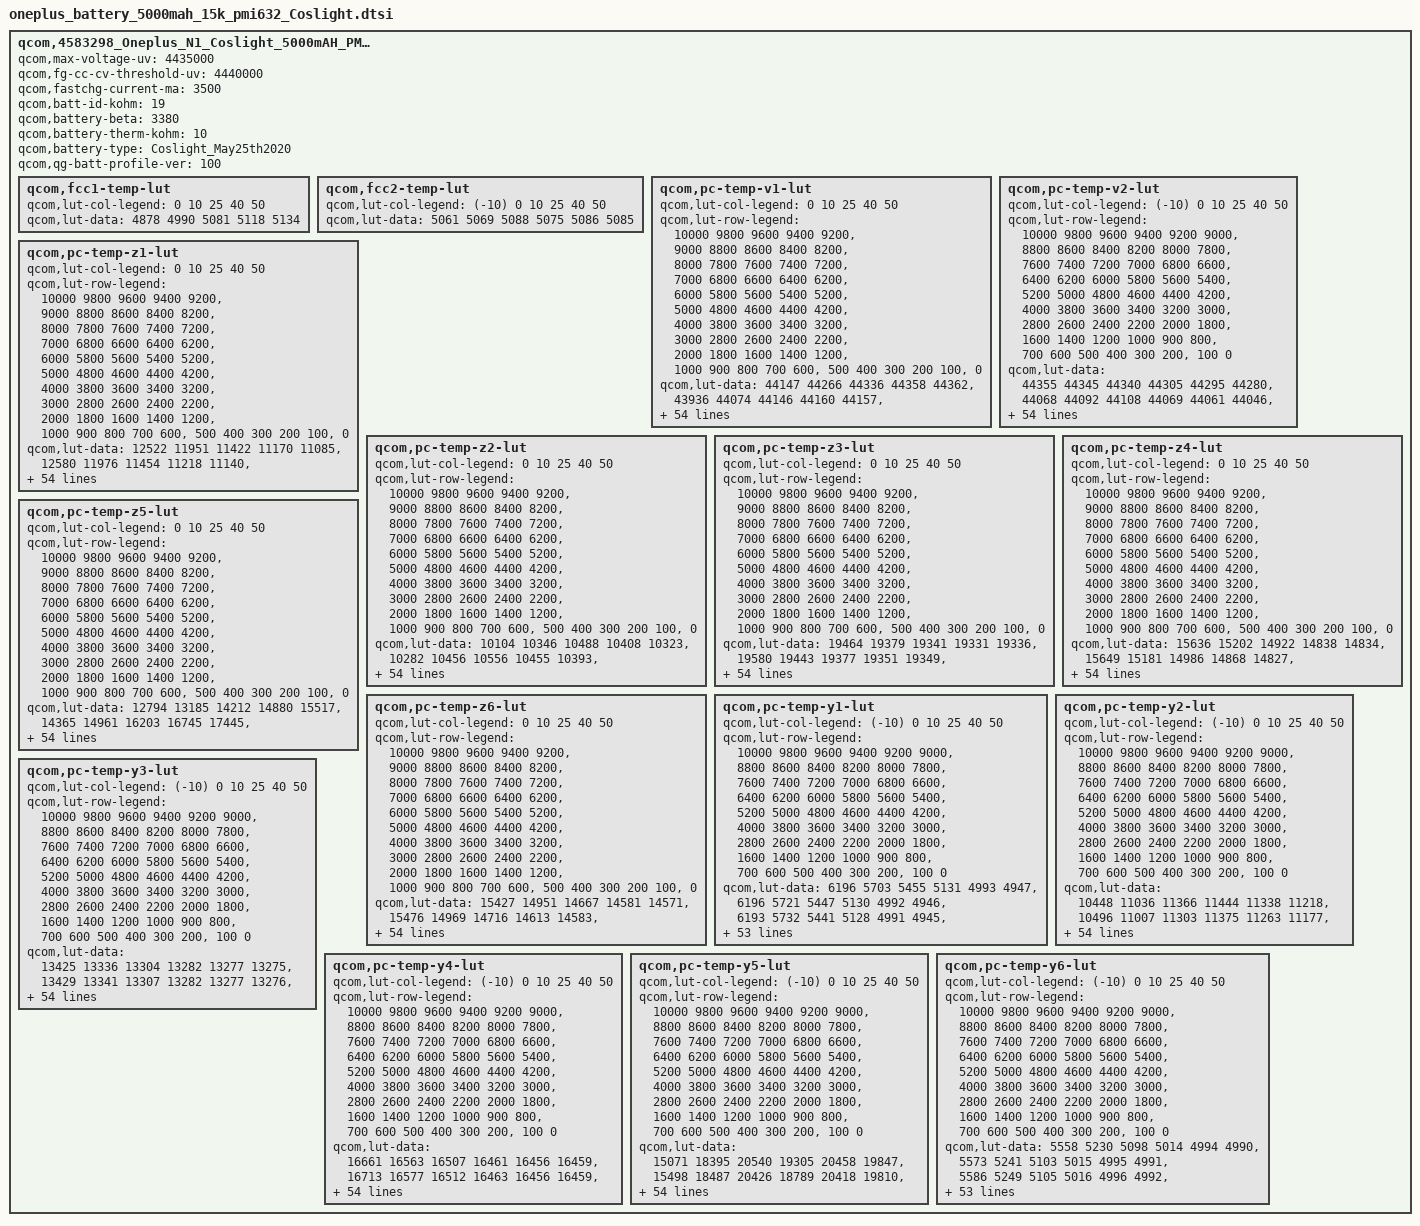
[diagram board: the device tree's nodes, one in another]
qcom,4583298_Oneplus_N1_Coslight_5000mAH_PMI632 {
    /* 4583298_Oneplus_N1_Coslight_5000mAH_PMI632_averaged_MasterSlave_May25th2020 */
    qcom,max-voltage-uv = <4435000>;
    qcom,fg-cc-cv-threshold-uv = <4440000>;
    qcom,fastchg-current-ma = <3500>;
    qcom,batt-id-kohm = <19>;
    qcom,battery-beta = <3380>;
    qcom,battery-therm-kohm = <10>;
    qcom,battery-type = "Coslight_May25th2020";
    qcom,qg-batt-profile-ver = <100>;

	qcom,fcc1-temp-lut {
		qcom,lut-col-legend = <0 10 25 40 50>;
		qcom,lut-data = <4878 4990 5081 5118 5134>;
	};

	qcom,fcc2-temp-lut {
		qcom,lut-col-legend = <(-10) 0 10 25 40 50>;
		qcom,lut-data = <5061 5069 5088 5075 5086 5085>;
	};

	qcom,pc-temp-v1-lut {
		qcom,lut-col-legend = <0 10 25 40 50>;
		qcom,lut-row-legend = <10000 9800 9600 9400 9200>,
			<9000 8800 8600 8400 8200>,
			<8000 7800 7600 7400 7200>,
			<7000 6800 6600 6400 6200>,
			<6000 5800 5600 5400 5200>,
			<5000 4800 4600 4400 4200>,
			<4000 3800 3600 3400 3200>,
			<3000 2800 2600 2400 2200>,
			<2000 1800 1600 1400 1200>,
			<1000 900 800 700 600>,
			<500 400 300 200 100>,
			<0>;
		qcom,lut-data = <44147 44266 44336 44358 44362>,
			<43936 44074 44146 44160 44157>,
			<43718 43872 43955 43970 43971>,
			<43496 43660 43757 43776 43778>,
			<43267 43437 43546 43571 43574>,
			<43026 43206 43322 43352 43359>,
			<42779 42966 43089 43123 43132>,
			<42536 42720 42845 42885 42895>,
			<42294 42474 42595 42638 42646>,
			<42056 42227 42347 42391 42400>,
			<41822 41985 42099 42144 42155>,
			<41592 41747 41856 41899 41912>,
			<41371 41517 41615 41657 41672>,
			<41162 41295 41381 41419 41435>,
			<40952 41082 41159 41189 41204>,
			<40730 40869 40945 40965 40977>,
			<40502 40648 40730 40749 40757>,
			<40292 40429 40514 40542 40547>,
			<40101 40229 40308 40342 40345>,
			<39922 40047 40127 40155 40156>,
			<39756 39862 39951 39977 39980>,
			<39602 39664 39721 39767 39777>,
			<39436 39460 39412 39481 39503>,
			<39238 39239 39160 39219 39239>,
			<39036 38989 39011 39055 39068>,
			<38864 38803 38893 38929 38938>,
			<38706 38705 38781 38806 38812>,
			<38588 38632 38677 38685 38689>,
			<38514 38555 38579 38575 38576>,
			<38457 38480 38484 38475 38474>,
			<38404 38411 38396 38384 38382>,
			<38356 38344 38318 38303 38297>,
			<38312 38284 38249 38229 38220>,
			<38273 38229 38185 38161 38147>,
			<38238 38180 38129 38097 38079>,
			<38203 38135 38077 38037 38012>,
			<38172 38097 38028 37977 37943>,
			<38135 38059 37983 37918 37871>,
			<38075 38000 37922 37847 37789>,
			<37987 37907 37830 37753 37689>,
			<37883 37799 37720 37643 37576>,
			<37756 37680 37604 37523 37454>,
			<37610 37541 37471 37387 37317>,
			<37440 37371 37306 37224 37152>,
			<37289 37223 37158 37083 37014>,
			<37196 37130 37071 37003 36944>,
			<37163 37105 37045 36976 36923>,
			<37146 37082 37028 36960 36903>,
			<37120 37067 37009 36940 36880>,
			<37078 37026 36961 36880 36809>,
			<36887 36803 36722 36609 36522>,
			<36440 36359 36277 36163 36071>,
			<35842 35765 35684 35573 35482>,
			<35010 34942 34871 34762 34669>,
			<33703 33627 33598 33496 33401>,
			<30000 30000 30000 30000 30000>;
	};

	qcom,pc-temp-v2-lut {
		qcom,lut-col-legend = <(-10) 0 10 25 40 50>;
		qcom,lut-row-legend = <10000 9800 9600 9400 9200 9000>,
			<8800 8600 8400 8200 8000 7800>,
			<7600 7400 7200 7000 6800 6600>,
			<6400 6200 6000 5800 5600 5400>,
			<5200 5000 4800 4600 4400 4200>,
			<4000 3800 3600 3400 3200 3000>,
			<2800 2600 2400 2200 2000 1800>,
			<1600 1400 1200 1000 900 800>,
			<700 600 500 400 300 200>,
			<100 0>;
		qcom,lut-data = <44355 44345 44340 44305 44295 44280>,
			<44068 44092 44108 44069 44061 44046>,
			<43802 43850 43882 43840 43833 43818>,
			<43557 43622 43665 43620 43615 43600>,
			<43336 43410 43457 43409 43405 43390>,
			<43110 43189 43240 43190 43187 43174>,
			<42870 42947 43002 42953 42951 42940>,
			<42624 42698 42756 42707 42708 42700>,
			<42379 42450 42509 42461 42464 42457>,
			<42132 42201 42260 42213 42216 42210>,
			<41889 41957 42013 41967 41971 41964>,
			<41654 41721 41771 41726 41729 41722>,
			<41419 41491 41531 41488 41490 41483>,
			<41170 41269 41297 41254 41255 41249>,
			<40913 41052 41067 41025 41025 41020>,
			<40653 40828 40845 40804 40803 40798>,
			<40393 40592 40634 40590 40590 40583>,
			<40134 40344 40421 40381 40383 40375>,
			<39874 40074 40189 40182 40188 40181>,
			<39614 39786 39946 39988 39999 39994>,
			<39391 39540 39703 39774 39792 39791>,
			<39209 39337 39450 39521 39557 39562>,
			<39043 39155 39219 39274 39323 39334>,
			<38880 38981 39030 39064 39105 39115>,
			<38723 38819 38866 38874 38899 38906>,
			<38568 38672 38717 38718 38737 38741>,
			<38405 38537 38582 38589 38608 38611>,
			<38261 38413 38462 38476 38494 38497>,
			<38152 38301 38354 38371 38386 38387>,
			<38059 38197 38255 38274 38287 38287>,
			<37987 38098 38163 38185 38199 38196>,
			<37931 37999 38075 38101 38118 38115>,
			<37879 37918 37995 38024 38042 38038>,
			<37827 37863 37920 37956 37972 37967>,
			<37777 37820 37851 37891 37901 37894>,
			<37722 37779 37794 37820 37815 37800>,
			<37660 37743 37745 37745 37717 37679>,
			<37592 37702 37693 37667 37617 37566>,
			<37515 37645 37635 37586 37522 37471>,
			<37431 37577 37569 37501 37428 37379>,
			<37343 37495 37483 37413 37339 37289>,
			<37248 37390 37372 37318 37249 37196>,
			<37152 37249 37240 37193 37122 37069>,
			<37056 37080 37090 37048 36976 36924>,
			<36964 36941 36951 36927 36861 36807>,
			<36861 36853 36885 36881 36826 36775>,
			<36811 36817 36864 36866 36815 36762>,
			<36755 36778 36840 36853 36801 36747>,
			<36689 36727 36800 36827 36774 36717>,
			<36581 36638 36725 36756 36682 36603>,
			<36400 36434 36485 36512 36374 36269>,
			<36033 36001 35990 36012 35864 35749>,
			<35433 35368 35294 35360 35194 35069>,
			<34540 34473 34345 34460 34249 34114>,
			<33077 32992 32823 33137 32885 32763>,
			<28483 28232 27916 27904 28040 28070>;
	};

	qcom,pc-temp-z1-lut {
		qcom,lut-col-legend = <0 10 25 40 50>;
		qcom,lut-row-legend = <10000 9800 9600 9400 9200>,
			<9000 8800 8600 8400 8200>,
			<8000 7800 7600 7400 7200>,
			<7000 6800 6600 6400 6200>,
			<6000 5800 5600 5400 5200>,
			<5000 4800 4600 4400 4200>,
			<4000 3800 3600 3400 3200>,
			<3000 2800 2600 2400 2200>,
			<2000 1800 1600 1400 1200>,
			<1000 900 800 700 600>,
			<500 400 300 200 100>,
			<0>;
		qcom,lut-data = <12522 11951 11422 11170 11085>,
			<12580 11976 11454 11218 11140>,
			<12587 11990 11457 11222 11147>,
			<12580 11986 11457 11225 11148>,
			<12570 11973 11454 11224 11148>,
			<12544 11960 11450 11222 11148>,
			<12511 11950 11445 11220 11148>,
			<12489 11938 11437 11217 11148>,
			<12472 11925 11429 11215 11147>,
			<12459 11907 11425 11213 11146>,
			<12450 11893 11421 11212 11145>,
			<12443 11883 11418 11210 11145>,
			<12434 11876 11416 11209 11143>,
			<12423 11872 11415 11208 11142>,
			<12410 11870 11414 11207 11142>,
			<12386 11869 11414 11206 11142>,
			<12355 11865 11413 11205 11141>,
			<12344 11861 11410 11205 11141>,
			<12346 11858 11408 11204 11142>,
			<12350 11854 11409 11205 11142>,
			<12358 11852 11411 11206 11142>,
			<12375 11854 11412 11206 11142>,
			<12385 11856 11413 11206 11143>,
			<12387 11858 11415 11206 11143>,
			<12387 11862 11418 11207 11144>,
			<12384 11865 11422 11210 11146>,
			<12374 11872 11425 11213 11148>,
			<12369 11879 11429 11217 11151>,
			<12377 11881 11432 11220 11155>,
			<12390 11882 11437 11223 11158>,
			<12393 11884 11442 11227 11161>,
			<12391 11888 11447 11229 11163>,
			<12391 11895 11451 11231 11166>,
			<12399 11902 11456 11234 11168>,
			<12416 11908 11460 11237 11171>,
			<12430 11914 11465 11241 11174>,
			<12444 11921 11470 11244 11176>,
			<12456 11930 11475 11247 11179>,
			<12465 11936 11481 11250 11181>,
			<12473 11941 11487 11253 11183>,
			<12475 11947 11492 11257 11186>,
			<12475 11957 11499 11260 11189>,
			<12481 11968 11506 11263 11192>,
			<12504 11981 11510 11266 11193>,
			<12521 11998 11517 11269 11195>,
			<12511 12008 11523 11272 11196>,
			<12510 12014 11521 11271 11196>,
			<12521 12004 11523 11271 11196>,
			<12537 11998 11526 11273 11198>,
			<12520 12021 11530 11277 11201>,
			<12553 12014 11540 11282 11206>,
			<12572 12042 11551 11288 11212>,
			<12577 12048 11567 11297 11219>,
			<12599 12087 11579 11310 11231>,
			<12599 12087 11579 11310 11231>,
			<12599 12087 11579 11310 11231>;
	};

	qcom,pc-temp-z2-lut {
		qcom,lut-col-legend = <0 10 25 40 50>;
		qcom,lut-row-legend = <10000 9800 9600 9400 9200>,
			<9000 8800 8600 8400 8200>,
			<8000 7800 7600 7400 7200>,
			<7000 6800 6600 6400 6200>,
			<6000 5800 5600 5400 5200>,
			<5000 4800 4600 4400 4200>,
			<4000 3800 3600 3400 3200>,
			<3000 2800 2600 2400 2200>,
			<2000 1800 1600 1400 1200>,
			<1000 900 800 700 600>,
			<500 400 300 200 100>,
			<0>;
		qcom,lut-data = <10104 10346 10488 10408 10323>,
			<10282 10456 10556 10455 10393>,
			<10305 10519 10614 10566 10361>,
			<10297 10520 10657 10612 10418>,
			<10286 10482 10646 10616 10440>,
			<10266 10440 10595 10572 10455>,
			<10242 10398 10549 10518 10470>,
			<10230 10359 10510 10472 10461>,
			<10224 10338 10481 10432 10442>,
			<10219 10323 10470 10412 10417>,
			<10210 10318 10463 10396 10353>,
			<10202 10323 10463 10388 10309>,
			<10200 10333 10475 10376 10278>,
			<10201 10346 10487 10360 10225>,
			<10203 10370 10492 10361 10227>,
			<10210 10395 10496 10373 10286>,
			<10224 10417 10498 10379 10324>,
			<10239 10436 10502 10355 10320>,
			<10258 10451 10506 10329 10315>,
			<10277 10463 10506 10340 10332>,
			<10292 10477 10510 10368 10363>,
			<10305 10512 10551 10421 10402>,
			<10322 10550 10708 10594 10529>,
			<10360 10562 10801 10732 10647>,
			<10401 10567 10676 10667 10630>,
			<10420 10568 10498 10529 10559>,
			<10431 10551 10488 10516 10544>,
			<10437 10528 10557 10681 10559>,
			<10436 10525 10607 10802 10565>,
			<10433 10529 10638 10723 10463>,
			<10433 10535 10664 10561 10275>,
			<10437 10542 10658 10442 10221>,
			<10440 10552 10628 10336 10217>,
			<10441 10561 10616 10291 10223>,
			<10440 10571 10626 10321 10250>,
			<10441 10581 10642 10377 10299>,
			<10445 10589 10664 10435 10372>,
			<10450 10597 10702 10505 10489>,
			<10459 10610 10738 10561 10574>,
			<10470 10632 10777 10597 10625>,
			<10475 10644 10805 10632 10654>,
			<10474 10638 10811 10690 10647>,
			<10475 10629 10811 10745 10622>,
			<10483 10623 10797 10742 10674>,
			<10628 10686 10785 10694 10687>,
			<10704 10745 10756 10618 10538>,
			<10705 10741 10666 10625 10508>,
			<10751 10733 10687 10610 10521>,
			<10808 10930 10700 10638 10598>,
			<10831 11044 10756 10753 10715>,
			<10820 10862 10804 10619 10530>,
			<10594 10822 10716 10391 10260>,
			<10481 10809 10617 10316 10190>,
			<10233 10594 10537 10227 10114>,
			<10233 10594 10537 10227 10114>,
			<10233 10594 10537 10227 10114>;
	};

	qcom,pc-temp-z3-lut {
		qcom,lut-col-legend = <0 10 25 40 50>;
		qcom,lut-row-legend = <10000 9800 9600 9400 9200>,
			<9000 8800 8600 8400 8200>,
			<8000 7800 7600 7400 7200>,
			<7000 6800 6600 6400 6200>,
			<6000 5800 5600 5400 5200>,
			<5000 4800 4600 4400 4200>,
			<4000 3800 3600 3400 3200>,
			<3000 2800 2600 2400 2200>,
			<2000 1800 1600 1400 1200>,
			<1000 900 800 700 600>,
			<500 400 300 200 100>,
			<0>;
		qcom,lut-data = <19464 19379 19341 19331 19336>,
			<19580 19443 19377 19351 19349>,
			<19626 19488 19398 19365 19354>,
			<19650 19508 19411 19376 19366>,
			<19662 19521 19416 19384 19375>,
			<19669 19525 19420 19391 19381>,
			<19674 19523 19422 19395 19386>,
			<19673 19519 19423 19396 19391>,
			<19664 19516 19423 19397 19396>,
			<19656 19515 19421 19396 19397>,
			<19653 19513 19416 19392 19391>,
			<19651 19507 19412 19387 19385>,
			<19647 19498 19409 19384 19381>,
			<19637 19490 19406 19381 19376>,
			<19627 19482 19400 19377 19373>,
			<19621 19477 19393 19373 19370>,
			<19617 19474 19388 19368 19368>,
			<19610 19471 19385 19363 19365>,
			<19597 19470 19383 19358 19361>,
			<19586 19467 19380 19354 19355>,
			<19585 19465 19377 19350 19349>,
			<19585 19471 19380 19349 19346>,
			<19585 19481 19396 19356 19349>,
			<19594 19484 19406 19362 19352>,
			<19606 19486 19392 19353 19349>,
			<19608 19486 19373 19335 19341>,
			<19607 19481 19370 19335 19341>,
			<19606 19472 19371 19371 19372>,
			<19602 19470 19373 19398 19399>,
			<19595 19469 19385 19395 19395>,
			<19589 19469 19400 19389 19384>,
			<19586 19470 19401 19383 19376>,
			<19582 19472 19400 19376 19368>,
			<19579 19472 19399 19368 19361>,
			<19576 19471 19395 19361 19351>,
			<19573 19469 19391 19354 19342>,
			<19569 19466 19386 19349 19339>,
			<19564 19462 19380 19345 19337>,
			<19560 19458 19377 19343 19336>,
			<19555 19455 19377 19341 19335>,
			<19549 19452 19376 19339 19335>,
			<19543 19447 19373 19342 19337>,
			<19536 19442 19370 19348 19344>,
			<19528 19438 19368 19348 19349>,
			<19492 19422 19364 19347 19350>,
			<19454 19405 19353 19335 19338>,
			<19439 19397 19349 19333 19327>,
			<19330 19390 19343 19326 19321>,
			<19311 19327 19340 19321 19316>,
			<19306 19320 19336 19317 19313>,
			<19312 19381 19335 19337 19332>,
			<19330 19350 19343 19345 19342>,
			<19317 19335 19348 19345 19338>,
			<19327 19343 19347 19346 19342>,
			<19327 19343 19347 19346 19342>,
			<19327 19343 19347 19346 19342>;
	};

	qcom,pc-temp-z4-lut {
		qcom,lut-col-legend = <0 10 25 40 50>;
		qcom,lut-row-legend = <10000 9800 9600 9400 9200>,
			<9000 8800 8600 8400 8200>,
			<8000 7800 7600 7400 7200>,
			<7000 6800 6600 6400 6200>,
			<6000 5800 5600 5400 5200>,
			<5000 4800 4600 4400 4200>,
			<4000 3800 3600 3400 3200>,
			<3000 2800 2600 2400 2200>,
			<2000 1800 1600 1400 1200>,
			<1000 900 800 700 600>,
			<500 400 300 200 100>,
			<0>;
		qcom,lut-data = <15636 15202 14922 14838 14834>,
			<15649 15181 14986 14868 14827>,
			<15609 15147 14953 14866 14841>,
			<15452 15097 14903 14836 14820>,
			<15302 15017 14866 14811 14799>,
			<15202 14947 14833 14789 14780>,
			<15116 14902 14805 14769 14761>,
			<15050 14865 14782 14751 14743>,
			<14997 14832 14762 14735 14725>,
			<14952 14804 14743 14723 14715>,
			<14911 14781 14727 14713 14707>,
			<14874 14764 14716 14705 14702>,
			<14845 14750 14710 14700 14700>,
			<14820 14740 14705 14696 14697>,
			<14801 14732 14700 14692 14693>,
			<14787 14728 14697 14687 14688>,
			<14777 14726 14695 14684 14683>,
			<14772 14725 14693 14682 14680>,
			<14770 14721 14692 14680 14678>,
			<14768 14712 14688 14678 14677>,
			<14761 14707 14683 14675 14675>,
			<14746 14712 14693 14678 14677>,
			<14739 14723 14754 14733 14730>,
			<14754 14747 14799 14789 14786>,
			<14780 14804 14810 14802 14790>,
			<14804 14837 14817 14810 14789>,
			<14830 14828 14814 14805 14783>,
			<14843 14811 14797 14751 14735>,
			<14839 14796 14776 14705 14692>,
			<14829 14781 14750 14696 14688>,
			<14819 14767 14724 14690 14686>,
			<14809 14754 14711 14687 14683>,
			<14799 14743 14702 14684 14680>,
			<14791 14737 14698 14682 14677>,
			<14782 14732 14696 14682 14677>,
			<14773 14728 14695 14683 14677>,
			<14762 14723 14694 14683 14677>,
			<14753 14718 14694 14684 14679>,
			<14745 14717 14694 14685 14681>,
			<14739 14716 14700 14694 14691>,
			<14731 14715 14705 14703 14700>,
			<14723 14708 14700 14698 14696>,
			<14713 14696 14692 14688 14686>,
			<14702 14689 14690 14690 14688>,
			<14678 14671 14679 14684 14683>,
			<14680 14655 14658 14663 14660>,
			<14691 14654 14653 14656 14658>,
			<14809 14654 14644 14647 14648>,
			<14825 14716 14633 14631 14630>,
			<14824 14718 14633 14626 14622>,
			<14814 14658 14657 14645 14649>,
			<14807 14703 14659 14649 14656>,
			<14829 14724 14657 14652 14663>,
			<14833 14723 14662 14653 14660>,
			<14833 14723 14662 14653 14660>,
			<14833 14723 14662 14653 14660>;
	};

	qcom,pc-temp-z5-lut {
		qcom,lut-col-legend = <0 10 25 40 50>;
		qcom,lut-row-legend = <10000 9800 9600 9400 9200>,
			<9000 8800 8600 8400 8200>,
			<8000 7800 7600 7400 7200>,
			<7000 6800 6600 6400 6200>,
			<6000 5800 5600 5400 5200>,
			<5000 4800 4600 4400 4200>,
			<4000 3800 3600 3400 3200>,
			<3000 2800 2600 2400 2200>,
			<2000 1800 1600 1400 1200>,
			<1000 900 800 700 600>,
			<500 400 300 200 100>,
			<0>;
		qcom,lut-data = <12794 13185 14212 14880 15517>,
			<14365 14961 16203 16745 17445>,
			<15062 16341 17434 17772 17729>,
			<15419 17215 18257 18882 19130>,
			<15770 17848 18635 19718 20289>,
			<16258 18259 18867 20376 21074>,
			<16786 18470 19158 20987 21946>,
			<17199 18646 19606 21593 23627>,
			<17501 19057 20147 22187 25882>,
			<17881 19925 20757 22728 26904>,
			<18634 20750 21451 23254 26897>,
			<19668 21374 22115 23681 26787>,
			<20495 21911 22878 24186 26625>,
			<21095 22303 23339 24779 26340>,
			<21802 22713 23156 25225 26815>,
			<23337 23083 22770 25579 28155>,
			<25447 23755 22728 25719 29395>,
			<26096 24743 23177 25572 30332>,
			<25177 25535 23629 25453 31036>,
			<24226 26374 23979 25718 30987>,
			<25078 27730 24640 26211 30284>,
			<28756 34406 27381 26765 29965>,
			<33660 42846 37362 28036 28936>,
			<43312 44029 43313 28996 27166>,
			<52710 42680 35160 25502 23818>,
			<53759 40902 23116 18161 18318>,
			<52231 36219 20151 16803 17211>,
			<50154 30469 19251 21351 23443>,
			<46600 29177 19010 25566 28756>,
			<42296 28958 21292 27258 28950>,
			<40000 28887 25006 28459 28981>,
			<38562 30294 27843 28953 29138>,
			<37803 33023 30549 29250 29650>,
			<37631 35409 32816 29442 29964>,
			<37564 37925 35035 29663 28975>,
			<37627 39312 36475 29865 27551>,
			<37915 39516 36199 29842 27674>,
			<38365 39586 35111 29609 28974>,
			<39205 39609 34233 29179 29554>,
			<40469 39692 33650 27320 27396>,
			<40859 39649 32942 25548 24977>,
			<39172 38034 31269 25897 25387>,
			<37936 36187 29361 26912 27284>,
			<37621 35733 28933 27240 29862>,
			<37010 35630 29752 27880 31590>,
			<26452 32735 28417 24716 26738>,
			<23455 27667 27032 24212 21035>,
			<12919 24844 25515 22998 21138>,
			<12363 14092 26629 26735 25031>,
			<12275 13906 25454 26581 29492>,
			<12577 23151 20620 27416 26399>,
			<13010 15935 19391 24014 23319>,
			<12406 14366 19854 21479 19254>,
			<12433 14566 18297 19497 18136>,
			<12433 14566 18297 19497 18136>,
			<12433 14566 18297 19497 18136>;
	};

	qcom,pc-temp-z6-lut {
		qcom,lut-col-legend = <0 10 25 40 50>;
		qcom,lut-row-legend = <10000 9800 9600 9400 9200>,
			<9000 8800 8600 8400 8200>,
			<8000 7800 7600 7400 7200>,
			<7000 6800 6600 6400 6200>,
			<6000 5800 5600 5400 5200>,
			<5000 4800 4600 4400 4200>,
			<4000 3800 3600 3400 3200>,
			<3000 2800 2600 2400 2200>,
			<2000 1800 1600 1400 1200>,
			<1000 900 800 700 600>,
			<500 400 300 200 100>,
			<0>;
		qcom,lut-data = <15427 14951 14667 14581 14571>,
			<15476 14969 14716 14613 14583>,
			<15464 14973 14710 14617 14591>,
			<15393 14966 14699 14613 14590>,
			<15322 14930 14689 14609 14588>,
			<15270 14893 14675 14603 14583>,
			<15224 14867 14663 14596 14578>,
			<15182 14844 14653 14590 14574>,
			<15144 14824 14643 14584 14570>,
			<15111 14808 14633 14577 14565>,
			<15084 14793 14623 14570 14559>,
			<15060 14779 14616 14564 14553>,
			<15038 14766 14611 14560 14549>,
			<15016 14757 14606 14556 14545>,
			<14997 14748 14601 14552 14541>,
			<14984 14742 14595 14547 14537>,
			<14974 14738 14591 14543 14533>,
			<14965 14735 14589 14539 14530>,
			<14957 14731 14586 14535 14527>,
			<14951 14726 14582 14531 14523>,
			<14946 14724 14579 14528 14518>,
			<14942 14729 14585 14529 14517>,
			<14941 14739 14622 14558 14542>,
			<14953 14754 14645 14584 14567>,
			<14972 14780 14642 14583 14568>,
			<14986 14794 14638 14580 14565>,
			<14998 14789 14633 14577 14562>,
			<15004 14779 14627 14573 14559>,
			<15001 14772 14622 14570 14556>,
			<14994 14766 14618 14566 14552>,
			<14988 14761 14615 14561 14547>,
			<14983 14758 14612 14556 14542>,
			<14979 14755 14608 14551 14537>,
			<14976 14754 14605 14547 14532>,
			<14973 14753 14603 14543 14526>,
			<14971 14751 14600 14540 14521>,
			<14967 14749 14598 14537 14520>,
			<14965 14748 14596 14534 14518>,
			<14965 14747 14595 14534 14518>,
			<14965 14748 14598 14537 14521>,
			<14966 14748 14600 14540 14525>,
			<14964 14745 14598 14539 14525>,
			<14963 14741 14594 14539 14525>,
			<14963 14739 14593 14540 14528>,
			<14949 14730 14588 14537 14527>,
			<14934 14718 14574 14522 14510>,
			<14932 14714 14570 14518 14505>,
			<14929 14711 14563 14510 14497>,
			<14927 14707 14557 14501 14486>,
			<14928 14708 14556 14497 14481>,
			<14935 14717 14568 14516 14504>,
			<14950 14726 14575 14525 14515>,
			<14964 14734 14580 14529 14519>,
			<14989 14749 14586 14533 14523>,
			<14989 14749 14586 14533 14523>,
			<14989 14749 14586 14533 14523>;
	};

	qcom,pc-temp-y1-lut {
		qcom,lut-col-legend = <(-10) 0 10 25 40 50>;
		qcom,lut-row-legend = <10000 9800 9600 9400 9200 9000>,
			<8800 8600 8400 8200 8000 7800>,
			<7600 7400 7200 7000 6800 6600>,
			<6400 6200 6000 5800 5600 5400>,
			<5200 5000 4800 4600 4400 4200>,
			<4000 3800 3600 3400 3200 3000>,
			<2800 2600 2400 2200 2000 1800>,
			<1600 1400 1200 1000 900 800>,
			<700 600 500 400 300 200>,
			<100 0>;
		qcom,lut-data = <6196 5703 5455 5131 4993 4947>,
			<6196 5721 5447 5130 4992 4946>,
			<6193 5732 5441 5128 4991 4945>,
			<6189 5737 5434 5126 4990 4944>,
			<6186 5739 5429 5124 4988 4944>,
			<6186 5738 5424 5121 4987 4943>,
			<6187 5731 5420 5118 4985 4943>,
			<6188 5722 5416 5115 4984 4942>,
			<6183 5716 5414 5112 4983 4942>,
			<6168 5711 5413 5110 4982 4941>,
			<6159 5709 5410 5108 4981 4940>,
			<6167 5711 5404 5107 4980 4939>,
			<6177 5715 5398 5106 4979 4938>,
			<6171 5717 5394 5105 4979 4938>,
			<6150 5720 5390 5104 4978 4939>,
			<6142 5721 5389 5103 4978 4939>,
			<6153 5715 5387 5102 4978 4939>,
			<6168 5709 5386 5102 4978 4939>,
			<6180 5710 5386 5102 4978 4939>,
			<6192 5715 5387 5104 4979 4939>,
			<6198 5717 5388 5106 4979 4940>,
			<6194 5713 5392 5106 4979 4940>,
			<6188 5710 5396 5107 4980 4940>,
			<6179 5712 5397 5109 4980 4940>,
			<6159 5717 5398 5112 4981 4941>,
			<6153 5719 5398 5114 4982 4942>,
			<6163 5722 5399 5116 4983 4943>,
			<6172 5724 5400 5118 4985 4943>,
			<6174 5723 5403 5121 4986 4945>,
			<6178 5722 5407 5124 4988 4947>,
			<6176 5723 5409 5127 4990 4949>,
			<6157 5729 5410 5130 4993 4951>,
			<6143 5733 5411 5134 4995 4953>,
			<6148 5734 5414 5138 4998 4954>,
			<6159 5734 5419 5141 5000 4956>,
			<6166 5736 5426 5144 5002 4957>,
			<6173 5740 5435 5147 5003 4959>,
			<6177 5742 5439 5149 5005 4961>,
			<6178 5739 5434 5152 5005 4963>,
			<6177 5735 5429 5154 5006 4964>,
			<6169 5738 5433 5156 5007 4964>,
			<6158 5749 5443 5159 5009 4965>,
			<6155 5752 5448 5161 5010 4966>,
			<6160 5752 5452 5163 5012 4969>,
			<6137 5745 5453 5170 5017 4972>,
			<6160 5750 5456 5174 5019 4973>,
			<6170 5754 5463 5175 5019 4973>,
			<6156 5769 5470 5176 5018 4972>,
			<6172 5772 5476 5176 5018 4973>,
			<6180 5754 5479 5176 5019 4973>,
			<6170 5754 5487 5177 5021 4975>,
			<6223 5770 5504 5186 5026 4979>,
			<6268 5793 5506 5201 5032 4985>,
			<6404 5829 5521 5218 5040 4992>,
			<6404 5829 5521 5218 5040 4992>,
			<6404 5829 5521 5218 5040 4992>;
	};

	qcom,pc-temp-y2-lut {
		qcom,lut-col-legend = <(-10) 0 10 25 40 50>;
		qcom,lut-row-legend = <10000 9800 9600 9400 9200 9000>,
			<8800 8600 8400 8200 8000 7800>,
			<7600 7400 7200 7000 6800 6600>,
			<6400 6200 6000 5800 5600 5400>,
			<5200 5000 4800 4600 4400 4200>,
			<4000 3800 3600 3400 3200 3000>,
			<2800 2600 2400 2200 2000 1800>,
			<1600 1400 1200 1000 900 800>,
			<700 600 500 400 300 200>,
			<100 0>;
		qcom,lut-data = <10448 11036 11366 11444 11338 11218>,
			<10496 11007 11303 11375 11263 11177>,
			<10552 10979 11236 11296 11187 11136>,
			<10608 10953 11171 11218 11116 11096>,
			<10653 10930 11114 11152 11053 11056>,
			<10680 10912 11070 11109 11003 11018>,
			<10692 10895 11032 11081 10956 10979>,
			<10701 10883 11003 11060 10922 10942>,
			<10720 10884 10993 11052 10918 10903>,
			<10752 10895 10987 11045 10921 10860>,
			<10770 10909 10985 11042 10922 10839>,
			<10773 10932 10993 11037 10922 10839>,
			<10776 10959 11009 11033 10920 10841>,
			<10819 10980 11032 11040 10909 10835>,
			<10945 10998 11072 11054 10891 10824>,
			<11001 11027 11113 11073 10886 10816>,
			<10982 11106 11152 11103 10908 10811>,
			<10961 11176 11193 11147 10948 10807>,
			<10962 11172 11251 11244 11004 10835>,
			<10969 11152 11316 11393 11088 10919>,
			<10980 11147 11332 11440 11180 11015>,
			<11003 11168 11320 11431 11316 11174>,
			<11026 11194 11311 11417 11403 11280>,
			<11035 11205 11317 11393 11371 11267>,
			<11041 11213 11332 11360 11307 11239>,
			<11040 11224 11346 11356 11296 11235>,
			<11010 11243 11360 11406 11334 11254>,
			<10961 11257 11376 11449 11377 11280>,
			<10801 11258 11400 11462 11410 11318>,
			<10518 11259 11426 11478 11448 11376>,
			<10362 11258 11437 11503 11492 11440>,
			<10064 11257 11445 11557 11546 11519>,
			<9813 11255 11448 11601 11596 11596>,
			<9758 11244 11441 11615 11648 11677>,
			<9726 11222 11430 11618 11691 11740>,
			<9706 11201 11424 11612 11671 11726>,
			<9692 11179 11421 11583 11565 11631>,
			<9683 11151 11414 11551 11479 11533>,
			<9677 11108 11380 11516 11432 11434>,
			<9673 11050 11332 11482 11396 11353>,
			<9670 10983 11299 11466 11366 11336>,
			<9667 10897 11267 11455 11344 11347>,
			<9665 10674 11206 11434 11334 11352>,
			<9664 10292 11124 11411 11330 11324>,
			<9662 9833 11083 11387 11265 11129>,
			<9661 9755 10995 11314 11081 10939>,
			<9660 9712 10960 11270 11064 10911>,
			<9659 9693 10936 11315 11110 10900>,
			<9657 9681 10891 11322 11137 10983>,
			<9656 9672 10841 11355 11099 10947>,
			<9654 9666 10739 11340 11028 10866>,
			<9652 9661 10271 11203 10932 10787>,
			<9650 9655 9879 11079 10819 10681>,
			<9649 9652 9692 10973 10654 10512>,
			<9649 9652 9692 10973 10654 10512>,
			<9649 9652 9692 10973 10654 10512>;
	};

	qcom,pc-temp-y3-lut {
		qcom,lut-col-legend = <(-10) 0 10 25 40 50>;
		qcom,lut-row-legend = <10000 9800 9600 9400 9200 9000>,
			<8800 8600 8400 8200 8000 7800>,
			<7600 7400 7200 7000 6800 6600>,
			<6400 6200 6000 5800 5600 5400>,
			<5200 5000 4800 4600 4400 4200>,
			<4000 3800 3600 3400 3200 3000>,
			<2800 2600 2400 2200 2000 1800>,
			<1600 1400 1200 1000 900 800>,
			<700 600 500 400 300 200>,
			<100 0>;
		qcom,lut-data = <13425 13336 13304 13282 13277 13275>,
			<13429 13341 13307 13282 13277 13276>,
			<13436 13347 13310 13283 13278 13276>,
			<13442 13352 13312 13283 13279 13277>,
			<13447 13356 13315 13284 13280 13278>,
			<13449 13359 13316 13285 13280 13279>,
			<13448 13361 13317 13286 13281 13280>,
			<13447 13362 13318 13287 13281 13280>,
			<13447 13362 13319 13287 13282 13281>,
			<13447 13361 13320 13288 13282 13281>,
			<13447 13360 13320 13289 13283 13282>,
			<13452 13360 13321 13291 13284 13282>,
			<13457 13360 13321 13292 13285 13282>,
			<13449 13361 13321 13293 13285 13283>,
			<13422 13365 13321 13295 13285 13283>,
			<13410 13367 13321 13296 13286 13284>,
			<13410 13362 13322 13297 13288 13285>,
			<13412 13356 13322 13298 13290 13286>,
			<13407 13351 13322 13298 13291 13287>,
			<13395 13346 13320 13297 13292 13289>,
			<13387 13342 13318 13296 13292 13289>,
			<13384 13338 13312 13294 13289 13287>,
			<13381 13336 13308 13291 13285 13285>,
			<13377 13333 13306 13287 13282 13281>,
			<13372 13331 13304 13283 13278 13277>,
			<13368 13329 13303 13282 13277 13276>,
			<13365 13327 13301 13282 13277 13276>,
			<13361 13326 13300 13282 13277 13277>,
			<13354 13325 13301 13282 13276 13276>,
			<13345 13324 13302 13283 13276 13276>,
			<13343 13322 13301 13283 13275 13276>,
			<13347 13320 13300 13283 13275 13276>,
			<13354 13318 13300 13283 13276 13276>,
			<13364 13319 13300 13283 13276 13277>,
			<13380 13321 13300 13283 13277 13277>,
			<13397 13323 13300 13283 13277 13277>,
			<13415 13326 13301 13283 13277 13276>,
			<13437 13329 13302 13283 13276 13276>,
			<13470 13331 13302 13283 13276 13276>,
			<13513 13333 13303 13282 13277 13277>,
			<13563 13336 13304 13283 13277 13278>,
			<13625 13339 13305 13284 13279 13279>,
			<13699 13340 13306 13283 13278 13278>,
			<13788 13339 13306 13282 13276 13276>,
			<13888 13347 13304 13282 13275 13275>,
			<13975 13365 13307 13284 13281 13281>,
			<14081 13387 13310 13286 13284 13283>,
			<14216 13416 13315 13291 13287 13285>,
			<14389 13458 13320 13294 13288 13286>,
			<14600 13524 13329 13295 13287 13284>,
			<14965 13633 13334 13293 13283 13282>,
			<15990 13848 13340 13291 13284 13283>,
			<18600 14498 13371 13295 13287 13286>,
			<25735 16330 13550 13302 13292 13293>,
			<25735 16330 13550 13302 13292 13293>,
			<25735 16330 13550 13302 13292 13293>;
	};

	qcom,pc-temp-y4-lut {
		qcom,lut-col-legend = <(-10) 0 10 25 40 50>;
		qcom,lut-row-legend = <10000 9800 9600 9400 9200 9000>,
			<8800 8600 8400 8200 8000 7800>,
			<7600 7400 7200 7000 6800 6600>,
			<6400 6200 6000 5800 5600 5400>,
			<5200 5000 4800 4600 4400 4200>,
			<4000 3800 3600 3400 3200 3000>,
			<2800 2600 2400 2200 2000 1800>,
			<1600 1400 1200 1000 900 800>,
			<700 600 500 400 300 200>,
			<100 0>;
		qcom,lut-data = <16661 16563 16507 16461 16456 16459>,
			<16713 16577 16512 16463 16456 16459>,
			<16783 16603 16518 16465 16456 16460>,
			<16855 16632 16524 16467 16457 16460>,
			<16915 16656 16529 16469 16457 16459>,
			<16946 16664 16531 16470 16458 16459>,
			<16957 16663 16530 16471 16458 16458>,
			<16964 16661 16529 16472 16459 16458>,
			<16965 16663 16530 16474 16459 16458>,
			<16965 16672 16534 16476 16460 16459>,
			<16964 16684 16539 16479 16462 16460>,
			<16953 16701 16548 16482 16464 16462>,
			<16939 16719 16560 16486 16467 16464>,
			<16949 16730 16575 16491 16471 16467>,
			<16987 16739 16593 16497 16476 16470>,
			<17003 16748 16615 16506 16482 16474>,
			<16958 16762 16646 16517 16486 16478>,
			<16889 16772 16667 16532 16492 16482>,
			<16831 16746 16664 16558 16505 16492>,
			<16773 16669 16651 16593 16524 16504>,
			<16745 16623 16632 16601 16532 16511>,
			<16736 16605 16578 16566 16529 16514>,
			<16728 16591 16529 16523 16522 16513>,
			<16714 16578 16511 16495 16500 16496>,
			<16694 16566 16500 16472 16468 16468>,
			<16667 16559 16497 16466 16460 16461>,
			<16620 16553 16496 16467 16461 16461>,
			<16588 16549 16495 16469 16462 16461>,
			<16594 16545 16497 16472 16466 16464>,
			<16610 16540 16499 16477 16473 16470>,
			<16621 16533 16502 16482 16481 16476>,
			<16640 16519 16504 16488 16490 16483>,
			<16658 16511 16505 16493 16497 16491>,
			<16668 16514 16503 16500 16504 16502>,
			<16675 16524 16499 16505 16508 16510>,
			<16682 16536 16500 16504 16505 16506>,
			<16690 16554 16504 16494 16492 16487>,
			<16694 16572 16509 16484 16480 16477>,
			<16693 16589 16516 16476 16472 16476>,
			<16690 16603 16521 16470 16467 16475>,
			<16687 16607 16521 16470 16470 16479>,
			<16682 16609 16520 16476 16478 16488>,
			<16683 16601 16519 16474 16474 16482>,
			<16692 16587 16516 16467 16459 16463>,
			<16702 16591 16499 16453 16443 16440>,
			<16702 16593 16505 16460 16457 16462>,
			<16717 16613 16520 16475 16479 16492>,
			<16738 16639 16540 16493 16509 16526>,
			<16764 16678 16574 16525 16545 16560>,
			<16790 16727 16620 16543 16546 16545>,
			<16811 16753 16611 16516 16487 16483>,
			<16978 16760 16617 16481 16467 16469>,
			<17504 16815 16655 16489 16468 16467>,
			<20218 17395 16742 16514 16476 16477>,
			<20218 17395 16742 16514 16476 16477>,
			<20218 17395 16742 16514 16476 16477>;
	};

	qcom,pc-temp-y5-lut {
		qcom,lut-col-legend = <(-10) 0 10 25 40 50>;
		qcom,lut-row-legend = <10000 9800 9600 9400 9200 9000>,
			<8800 8600 8400 8200 8000 7800>,
			<7600 7400 7200 7000 6800 6600>,
			<6400 6200 6000 5800 5600 5400>,
			<5200 5000 4800 4600 4400 4200>,
			<4000 3800 3600 3400 3200 3000>,
			<2800 2600 2400 2200 2000 1800>,
			<1600 1400 1200 1000 900 800>,
			<700 600 500 400 300 200>,
			<100 0>;
		qcom,lut-data = <15071 18395 20540 19305 20458 19847>,
			<15498 18487 20426 18789 20418 19810>,
			<15920 18538 20195 18232 20213 19795>,
			<16313 18558 19879 17689 19913 19795>,
			<16651 18555 19504 17215 19584 19805>,
			<16909 18538 19101 16868 19293 19821>,
			<17073 18295 18625 16629 18816 19888>,
			<17222 17857 18102 16413 18284 19912>,
			<17447 17379 17601 16149 18005 19626>,
			<17773 16744 17097 15839 17722 18912>,
			<18256 16476 16633 15647 17448 18348>,
			<19534 16527 16079 15697 17163 17910>,
			<20782 16645 15631 15813 16832 17456>,
			<20172 17155 15456 15770 16351 16994>,
			<17739 18516 15302 15585 15749 16479>,
			<16758 19575 15368 15409 15568 16166>,
			<19736 20265 16009 15158 15852 16105>,
			<22988 20920 17089 14961 16123 16115>,
			<22559 21785 19451 15096 16019 16057>,
			<20647 22856 22973 15628 15754 15973>,
			<19931 23175 23908 16599 15917 16153>,
			<20470 22876 23306 20040 18294 18151>,
			<21223 22538 22766 22849 20245 19806>,
			<21833 22427 22694 22029 20191 19586>,
			<22419 22404 22667 20051 19978 19078>,
			<22644 22402 22461 19339 19751 18882>,
			<22118 22394 21685 19218 19294 18833>,
			<21171 22439 21175 19206 18729 18759>,
			<19081 22882 22000 19542 17837 17979>,
			<15801 23609 23341 20161 16896 16805>,
			<14401 23569 23652 20507 16752 16539>,
			<13863 22050 23718 20704 16866 16547>,
			<13647 20900 23854 20905 17059 16636>,
			<13852 20957 24534 21471 18090 17617>,
			<14200 21227 25368 22354 19656 19118>,
			<14370 21585 25565 23135 20737 19921>,
			<14454 22318 25455 24053 21667 20423>,
			<14514 22769 25237 24479 22001 20952>,
			<14571 22654 24706 23709 21646 21707>,
			<14615 22458 23972 22592 21235 22362>,
			<14588 22546 23296 22280 21448 22452>,
			<14394 22850 22567 22031 22038 22289>,
			<14136 21489 21669 21178 21983 23468>,
			<13833 18371 20707 20346 21107 24038>,
			<13876 14938 20552 20836 18590 19707>,
			<13709 14656 20139 20130 18538 18822>,
			<13935 14472 20049 18759 18073 16579>,
			<14089 14288 19573 19446 17370 15652>,
			<14459 14376 18389 18873 16678 15359>,
			<14504 14611 18589 18523 15944 15012>,
			<15119 14909 18947 19379 17040 16027>,
			<12782 14234 16931 20283 17600 16603>,
			<10772 13572 14945 20491 17869 16882>,
			<9442 11023 14135 23034 21166 23594>,
			<9442 11023 14135 23034 21166 23594>,
			<9442 11023 14135 23034 21166 23594>;
	};

	qcom,pc-temp-y6-lut {
		qcom,lut-col-legend = <(-10) 0 10 25 40 50>;
		qcom,lut-row-legend = <10000 9800 9600 9400 9200 9000>,
			<8800 8600 8400 8200 8000 7800>,
			<7600 7400 7200 7000 6800 6600>,
			<6400 6200 6000 5800 5600 5400>,
			<5200 5000 4800 4600 4400 4200>,
			<4000 3800 3600 3400 3200 3000>,
			<2800 2600 2400 2200 2000 1800>,
			<1600 1400 1200 1000 900 800>,
			<700 600 500 400 300 200>,
			<100 0>;
		qcom,lut-data = <5558 5230 5098 5014 4994 4990>,
			<5573 5241 5103 5015 4995 4991>,
			<5586 5249 5105 5016 4996 4992>,
			<5596 5255 5107 5017 4997 4992>,
			<5603 5259 5108 5018 4998 4993>,
			<5605 5260 5108 5019 4998 4994>,
			<5602 5258 5107 5020 4999 4994>,
			<5597 5254 5105 5020 4999 4995>,
			<5593 5252 5105 5021 5000 4995>,
			<5591 5251 5105 5022 5001 4996>,
			<5588 5250 5105 5023 5002 4996>,
			<5584 5252 5107 5025 5003 4997>,
			<5579 5256 5110 5027 5004 4998>,
			<5574 5259 5113 5030 5005 4999>,
			<5567 5263 5117 5032 5007 5001>,
			<5559 5264 5122 5036 5009 5002>,
			<5548 5264 5131 5040 5012 5004>,
			<5533 5263 5137 5044 5015 5006>,
			<5515 5253 5135 5052 5020 5010>,
			<5494 5228 5130 5061 5026 5015>,
			<5486 5212 5123 5063 5027 5016>,
			<5485 5205 5104 5050 5024 5015>,
			<5485 5200 5087 5035 5019 5012>,
			<5483 5196 5081 5025 5010 5005>,
			<5481 5192 5077 5016 4998 4993>,
			<5478 5191 5076 5014 4995 4991>,
			<5474 5190 5075 5014 4995 4991>,
			<5471 5190 5074 5014 4995 4991>,
			<5473 5190 5076 5016 4996 4992>,
			<5481 5191 5078 5018 4998 4993>,
			<5492 5191 5080 5020 5000 4995>,
			<5509 5190 5082 5022 5003 4997>,
			<5530 5189 5082 5024 5005 5000>,
			<5554 5194 5082 5026 5008 5003>,
			<5583 5203 5083 5028 5010 5006>,
			<5614 5215 5084 5028 5009 5005>,
			<5648 5229 5087 5026 5005 4999>,
			<5685 5245 5092 5023 5002 4996>,
			<5727 5263 5096 5021 5000 4996>,
			<5773 5282 5100 5019 4998 4997>,
			<5823 5304 5103 5020 5000 4998>,
			<5880 5328 5107 5023 5003 5002>,
			<5948 5349 5111 5023 5002 5000>,
			<6032 5370 5116 5020 4996 4993>,
			<6121 5397 5114 5017 4992 4987>,
			<6206 5432 5123 5022 5000 4998>,
			<6300 5476 5135 5028 5009 5008>,
			<6418 5530 5151 5037 5019 5019>,
			<6571 5603 5172 5048 5031 5030>,
			<6758 5697 5203 5054 5031 5025>,
			<7070 5820 5219 5045 5011 5005>,
			<7959 6029 5253 5035 5007 5002>,
			<10064 6598 5356 5043 5010 5005>,
			<15636 8190 5621 5059 5017 5014>,
			<15636 8190 5621 5059 5017 5014>,
			<15636 8190 5621 5059 5017 5014>;
	};

};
